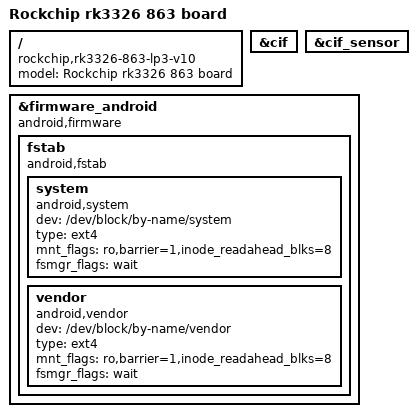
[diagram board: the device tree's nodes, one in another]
/*
 * Copyright (c) 2017 Fuzhou Rockchip Electronics Co., Ltd
 *
 * SPDX-License-Identifier: (GPL-2.0+ OR MIT)
 */

/dts-v1/;
#include "rk3326-863-lp3-v10.dtsi"

/ {
	model = "Rockchip rk3326 863 board";
	compatible = "rockchip,rk3326-863-lp3-v10", "rockchip,rk3326";
};

&cif {
	status = "okay";
};

&cif_sensor {
	status = "okay";
};

&firmware_android {
	compatible = "android,firmware";
	fstab {
		compatible = "android,fstab";
		system {
			compatible = "android,system";
			dev = "/dev/block/by-name/system";
			type = "ext4";
			mnt_flags = "ro,barrier=1,inode_readahead_blks=8";
			fsmgr_flags = "wait";
		};
		vendor {
			compatible = "android,vendor";
			dev = "/dev/block/by-name/vendor";
			type = "ext4";
			mnt_flags = "ro,barrier=1,inode_readahead_blks=8";
			fsmgr_flags = "wait";
		};
	};
};
